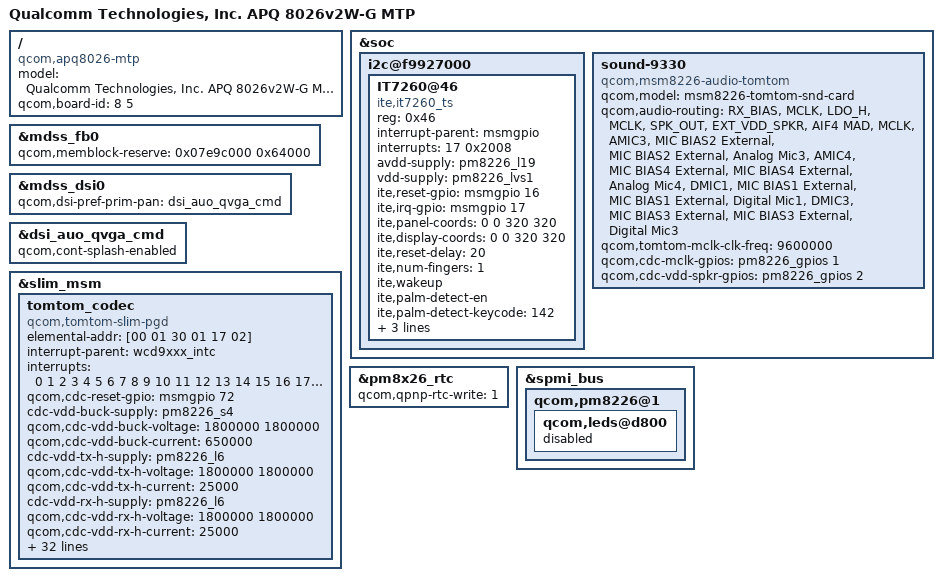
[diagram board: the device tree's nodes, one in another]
/* Copyright (c) 2015, The Linux Foundation. All rights reserved.
 *
 * This program is free software; you can redistribute it and/or modify
 * it under the terms of the GNU General Public License version 2 and
 * only version 2 as published by the Free Software Foundation.
 *
 * This program is distributed in the hope that it will be useful,
 * but WITHOUT ANY WARRANTY; without even the implied warranty of
 * MERCHANTABILITY or FITNESS FOR A PARTICULAR PURPOSE.  See the
 * GNU General Public License for more details.
 */


/dts-v1/;
#include "apq8026-v2.dtsi"
#include "msm8226-w-memory.dtsi"
#include "msm8226-w-qseecom.dtsi"
#include "msm8226-w-sharedmem.dtsi"
#include "msm8226-720p-mtp.dtsi"
#include "msm8x26w-gpu.dtsi"

/ {
	model = "Qualcomm Technologies, Inc. APQ 8026v2W-G MTP";
	compatible = "qcom,apq8026-mtp", "qcom,apq8026", "qcom,mtp";
	qcom,board-id = <8 5>;
};

&soc {
	i2c@f9927000 { /* BLSP1 QUP5 */
		IT7260@46 {
			compatible = "ite,it7260_ts";
			reg = <0x46>;
			interrupt-parent = <&msmgpio>;
			interrupts = <17 0x2008>;
			avdd-supply = <&pm8226_l19>;
			vdd-supply = <&pm8226_lvs1>;
			ite,reset-gpio = <&msmgpio 16 0x00>;
			ite,irq-gpio = <&msmgpio 17 0x2008>;
			ite,panel-coords = <0 0 320 320>;
			ite,display-coords = <0 0 320 320>;
			ite,reset-delay = <20>;
			ite,num-fingers = <1>;
			ite,wakeup;
			ite,palm-detect-en;
			ite,palm-detect-keycode = <142>;
			ite,low-reset;
			ite,fw-name = "it7260_fw.bin";
			ite,cfg-name = "it7260_cfg.bin";
		};
	};
};

&mdss_fb0 {
	/* cont_splash memory*/
	qcom,memblock-reserve = <0x07e9c000 0x64000>;
};

&mdss_dsi0 {
	qcom,dsi-pref-prim-pan = <&dsi_auo_qvga_cmd>;
};

&dsi_auo_qvga_cmd {
       qcom,cont-splash-enabled;
};

&soc {
	i2c@f9927000 { /* BLSP1 QUP5 */
		/delete-node/ synaptics@20;
	};

	sound-9330 {
		compatible = "qcom,msm8226-audio-tomtom";
		qcom,model = "msm8226-tomtom-snd-card";
		qcom,audio-routing =
			"RX_BIAS", "MCLK",
			"LDO_H", "MCLK",
			"SPK_OUT", "EXT_VDD_SPKR",
			"AIF4 MAD", "MCLK",
			"AMIC3", "MIC BIAS2 External",
			"MIC BIAS2 External", "Analog Mic3",
			"AMIC4", "MIC BIAS4 External",
			"MIC BIAS4 External", "Analog Mic4",
			"DMIC1", "MIC BIAS1 External",
			"MIC BIAS1 External", "Digital Mic1",
			"DMIC3", "MIC BIAS3 External",
			"MIC BIAS3 External", "Digital Mic3";

		qcom,tomtom-mclk-clk-freq = <9600000>;
		qcom,cdc-mclk-gpios = <&pm8226_gpios 1 0>;
		qcom,cdc-vdd-spkr-gpios = <&pm8226_gpios 2 0>;
	};
};

&slim_msm {
	tomtom_codec {
		compatible = "qcom,tomtom-slim-pgd";
		elemental-addr = [00 01 30 01 17 02];

		interrupt-parent = <&wcd9xxx_intc>;
		interrupts = <0 1 2 3 4 5 6 7 8 9 10 11 12 13 14 15 16
			      17 18 19 20 21 22 23 24 25 26 27 28 29
			      30 31>;

		qcom,cdc-reset-gpio = <&msmgpio 72 0>;

		cdc-vdd-buck-supply = <&pm8226_s4>;
		qcom,cdc-vdd-buck-voltage = <1800000 1800000>;
		qcom,cdc-vdd-buck-current = <650000>;

		cdc-vdd-tx-h-supply = <&pm8226_l6>;
		qcom,cdc-vdd-tx-h-voltage = <1800000 1800000>;
		qcom,cdc-vdd-tx-h-current = <25000>;

		cdc-vdd-rx-h-supply = <&pm8226_l6>;
		qcom,cdc-vdd-rx-h-voltage = <1800000 1800000>;
		qcom,cdc-vdd-rx-h-current = <25000>;

		cdc-vddpx-1-supply = <&pm8226_l6>;
		qcom,cdc-vddpx-1-voltage = <1800000 1800000>;
		qcom,cdc-vddpx-1-current = <10000>;

		cdc-vdd-a-1p2v-supply = <&pm8226_l4>;
		qcom,cdc-vdd-a-1p2v-voltage = <1200000 1200000>;
		qcom,cdc-vdd-a-1p2v-current = <2000>;
		qcom,cdc-vdd-a-1p2v-active-current = <2000>;

		cdc-vddcx-1-supply = <&pm8226_l4>;
		qcom,cdc-vddcx-1-voltage = <1200000 1200000>;
		qcom,cdc-vddcx-1-current = <2000>;
		qcom,cdc-vddcx-1-active-current = <33000>;

		cdc-vddcx-2-supply = <&pm8226_l4>;
		qcom,cdc-vddcx-2-voltage = <1200000 1200000>;
		qcom,cdc-vddcx-2-current = <2000>;
		qcom,cdc-vddcx-2-active-current = <33000>;

		qcom,cdc-static-supplies = "cdc-vdd-buck",
					   "cdc-vdd-tx-h",
					   "cdc-vdd-rx-h",
					   "cdc-vddpx-1",
					   "cdc-vdd-a-1p2v",
					   "cdc-vddcx-1",
					   "cdc-vddcx-2";

		qcom,cdc-micbias-ldoh-v = <0x3>;
		qcom,cdc-micbias-cfilt1-mv = <1800>;
		qcom,cdc-micbias-cfilt2-mv = <1800>;
		qcom,cdc-micbias-cfilt3-mv = <1800>;
		qcom,cdc-micbias1-cfilt-sel = <0x0>;
		qcom,cdc-micbias2-cfilt-sel = <0x1>;
		qcom,cdc-micbias3-cfilt-sel = <0x2>;
		qcom,cdc-micbias4-cfilt-sel = <0x2>;
		qcom,cdc-mclk-clk-rate = <9600000>;
		qcom,cdc-slim-ifd = "tomtom-slim-ifd";
		qcom,cdc-slim-ifd-elemental-addr = [00 00 30 01 17 02];
		qcom,cdc-dmic-sample-rate = <4800000>;
		qcom,cdc-variant = "WCD9330";
	};
};

&pm8x26_rtc {
	qcom,qpnp-rtc-write = <1>;
};

&spmi_bus {
	qcom,pm8226@1{
		qcom,leds@d800 {
			status = "disabled";
		};
	};
};
